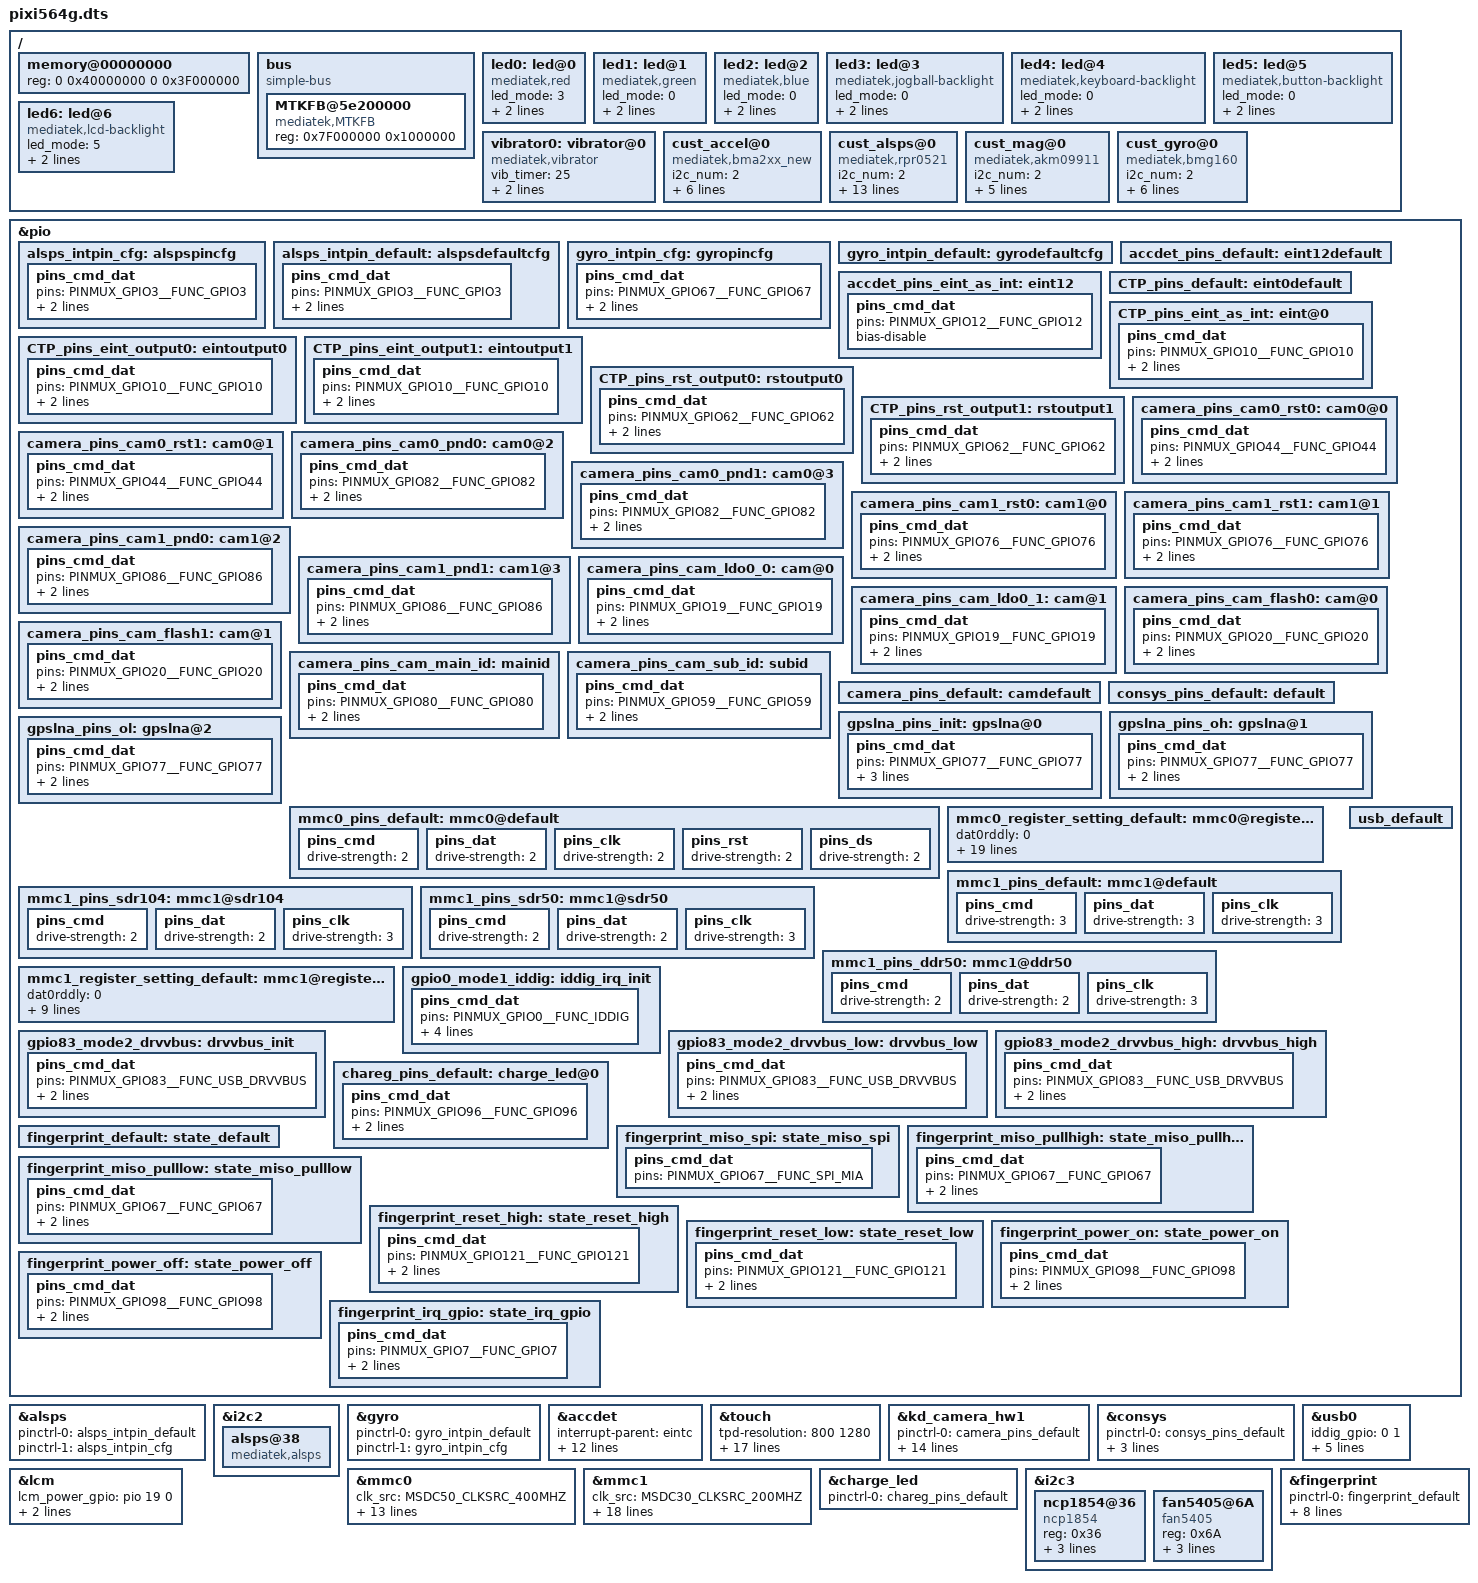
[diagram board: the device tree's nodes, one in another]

/dts-v1/;

#include "mt6735m.dtsi"
#include "pixi564g_bat_setting.dtsi"

/ {
memory@00000000 {
		device_type = "memory";
		reg = <0 0x40000000 0 0x3F000000>;
	};

	bus {
		compatible = "simple-bus";
		#address-cells = <1>;
		#size-cells = <1>;
		ranges = <0 0 0 0xffffffff>;

		MTKFB@5e200000 {
			compatible = "mediatek,MTKFB";
			reg = <0x7F000000 0x1000000>;
		};

	};
	led0:led@0 {
		compatible = "mediatek,red";
		led_mode = <3>;
		data = <1>;
		pwm_config = <0 0 0 0 0>;
	};
	led1:led@1 {
		compatible = "mediatek,green";
		led_mode = <0>;
		data = <1>;
		pwm_config = <0 0 0 0 0>;
	};
	led2:led@2 {
		compatible = "mediatek,blue";
		led_mode = <0>;
		data = <1>;
		pwm_config = <0 0 0 0 0>;
	};
	led3:led@3 {
		compatible = "mediatek,jogball-backlight";
		led_mode = <0>;
		data = <1>;
		pwm_config = <0 0 0 0 0>;
	};
	led4:led@4 {
		compatible = "mediatek,keyboard-backlight";
		led_mode = <0>;
		data = <1>;
		pwm_config = <0 0 0 0 0>;
	};
	led5:led@5 {
		compatible = "mediatek,button-backlight";
		led_mode = <0>;
		data = <1>;
		pwm_config = <0 0 0 0 0>;
	};
	led6:led@6 {
		compatible = "mediatek,lcd-backlight";
		led_mode = <5>;
		data = <1>;
		pwm_config = <0 0 0 0 0>;
	};
	vibrator0:vibrator@0 {
		compatible = "mediatek,vibrator";
		vib_timer = <25>;
		vib_limit = <9>;
		vib_vol= <5>;
	};
 /* sensor standardization */
	cust_accel@0 {
		compatible = "mediatek,bma2xx_new";
		i2c_num = <2>;
		i2c_addr = <0x18 0 0 0>;
		direction = <7>;
		power_id = <0xffff>;
		power_vol = <0>;
		firlen = <16>;
		is_batch_supported = <0>;
	};
/*
	cust_alsps@0 {
		compatible = "mediatek,apds9930";
		i2c_num = <2>;
		i2c_addr = <0x39 0x00 0x00 0x00>;
		polling_mode_ps = <0>;
		polling_mode_als = <1>;
		power_id = <0xffff>;
		power_vol = <0>;
		als_level = <1 2 5 10 20 30 40 80 200 300 400 600 1000 1600 2000>;
		als_value = <80 400 800 1200 1800 2000 2300 2300 12000 12000 12000 48000 48000 72000 81920 81920>;
		ps_threshold_high =  <90>;
		ps_threshold_low =  <70>;
		is_batch_supported_ps   = <0>;
		is_batch_supported_als  = <0>;
	};
*/
	cust_alsps@0 {
		compatible = "mediatek,rpr0521";
		i2c_num	= <2>;
		i2c_addr = <0x38 0 0 0>;
		polling_mode_ps	= <0>;
		polling_mode_als = <1>;
		power_id = <0xffff>;
		power_vol = <0>;
		als_level = <0 257 637 1027 2297 5588 6730 11301 20449 25768 31122 45552 57937 57937 57937>;
		als_value = <0 132 304 502 1004 2003 3006 5006 8004 10000 12000 16000 20000 20000 20000 20000>;
		ps_threshold_high = <1000>;
		ps_threshold_low = <999>;
		is_batch_supported_ps = <1>;
		is_batch_supported_als = <1>;
	};
	cust_mag@0 {
		compatible				= "mediatek,akm09911";
		i2c_num				= <2>;
		i2c_addr				= <0x0D 0 0 0>;
		direction				= <5>;
		power_id				= <0xffff>;
		power_vol				= <0>;
		is_batch_supported	= <0>;
		};
    cust_gyro@0 {
		compatible				= "mediatek,bmg160";
		i2c_num				= <2>;
		i2c_addr				= <0x66 0 0 0>;
		direction				= <4>;
		power_id				= <0xffff>;
		power_vol				= <0>;
		firlen					= <0>;
		is_batch_supported	= <0>;
		};
/*	cust_gyro@0 {
		compatible				= "mediatek,itg1010";
		i2c_num				= <2>;
		i2c_addr				= <0x68 0 0 0>;
		direction				= <3>;
		power_id				= <0xffff>;
		power_vol				= <0>;
		firlen					= <0>;
		is_batch_supported	= <0>;
		};
*/
};
/* sensor gpio standization */
&pio {
	alsps_intpin_cfg: alspspincfg {
		pins_cmd_dat {
			pins = <PINMUX_GPIO3__FUNC_GPIO3>;
			slew-rate = <0>;
			bias-pull-up = <00>;
		};
	};

	alsps_intpin_default: alspsdefaultcfg {
		pins_cmd_dat {
			pins = <PINMUX_GPIO3__FUNC_GPIO3>;
			slew-rate = <0>;
			bias-pull-up = <00>;
		};
	};

	gyro_intpin_cfg: gyropincfg {
		pins_cmd_dat {
			pins = <PINMUX_GPIO67__FUNC_GPIO67>;
			slew-rate = <0>;
			bias-pull-down = <00>;
		};
	};

	gyro_intpin_default: gyrodefaultcfg {

	};
};
&alsps {
	pinctrl-names = "default", "pin_cfg";
	pinctrl-0 = <&alsps_intpin_default>;
	pinctrl-1 = <&alsps_intpin_cfg>;
	status = "okay";
};
&i2c2 {
	alsps@38 {
		compatible = "mediatek,alsps";
		status = "okay";
	};
};

&gyro {
	pinctrl-names = "pin_default", "pin_cfg";
	pinctrl-0 = <&gyro_intpin_default>;
	pinctrl-1 = <&gyro_intpin_cfg>;
	status = "okay";

};
/* sensor end */

&accdet {
	interrupt-parent = <&eintc>;
	interrupts = <12 IRQ_TYPE_LEVEL_LOW>;
	eint-debounce = <256>;
	accdet-gpio = <&pio 12 0>;
	accdet-mic-vol = <3>;		/* [PLATFORM]-Add by TCTSZ.lizhi.wu, 2016.09.20, change micbias from 2.5 to 2.0*/
	headset-mode-setting = <0x500 0x500 1 0x1f0 0x800 0x800 0x20>;		/* [PLATFORM]-Add by TCTSZ.lizhi.wu, 2016.11.01, make micbias always on*/
	accdet-plugout-debounce = <20>;
	/*1:ACC mode, 2:low cost without in bias, 6:low cost with in bias*/
	accdet-mic-mode = <6>;
	/*0--MD_MAX--UP_MAX--DW_MAX*/
	headset-three-key-threshold = <0 80 220 500>;
	/*0--MD_MAX--VOICE_MAX--UP_MAX--DW_MAX*/
	headset-four-key-threshold = <0 58 121 192 450>;
	pinctrl-names = "default", "state_eint_as_int";
	pinctrl-0 = <&accdet_pins_default>;
	pinctrl-1 = <&accdet_pins_eint_as_int>;
	status = "okay";
};

&touch {
	tpd-resolution = <800 1280>;
	use-tpd-button = <0>;
	tpd-key-num = <3>;
	tpd-key-local= <139 172 158 0>;
	tpd-key-dim-local = <90 883 100 40 230 883 100 40 370 883 100 40 0 0 0 0>;
	tpd-max-touch-num = <5>;
	tpd-filter-enable = <1>;
	tpd-filter-pixel-density = <93>;
	tpd-filter-custom-prameters = <0 0 0 0 0 0 0 0 0 0 0 0>;
	tpd-filter-custom-speed = <0 0 0>;
	pinctrl-names = "default", "state_eint_as_int", "state_eint_output0", "state_eint_output1",
		"state_rst_output0", "state_rst_output1";
	pinctrl-0 = <&CTP_pins_default>;
	pinctrl-1 = <&CTP_pins_eint_as_int>;
	pinctrl-2 = <&CTP_pins_eint_output0>;
	pinctrl-3 = <&CTP_pins_eint_output1>;
	pinctrl-4 = <&CTP_pins_rst_output0>;
	pinctrl-5 = <&CTP_pins_rst_output1>;
	status = "okay";
};
&pio {
	accdet_pins_default: eint12default {
	};

	accdet_pins_eint_as_int: eint12 {
		pins_cmd_dat {
			pins = <PINMUX_GPIO12__FUNC_GPIO12>;
			bias-disable;
		};
	};

	CTP_pins_default: eint0default {
	};
	CTP_pins_eint_as_int: eint@0 {
		pins_cmd_dat {
			pins = <PINMUX_GPIO10__FUNC_GPIO10>;
			slew-rate = <0>;
			bias-disable;
		};
	};
	CTP_pins_eint_output0: eintoutput0 {
		pins_cmd_dat {
			pins = <PINMUX_GPIO10__FUNC_GPIO10>;
			slew-rate = <1>;
			output-low;
		};
	};
	CTP_pins_eint_output1: eintoutput1 {
		pins_cmd_dat {
			pins = <PINMUX_GPIO10__FUNC_GPIO10>;
			slew-rate = <1>;
			output-high;
		};
	};
	CTP_pins_rst_output0: rstoutput0 {
		pins_cmd_dat {
			pins = <PINMUX_GPIO62__FUNC_GPIO62>;
			slew-rate = <1>;
			output-low;
		};
	};
	CTP_pins_rst_output1: rstoutput1 {
		pins_cmd_dat {
			pins = <PINMUX_GPIO62__FUNC_GPIO62>;
			slew-rate = <1>;
			output-high;
		};
	};
};
/* TOUCH end */
/* CAMERA GPIO standardization */
&pio {
	camera_pins_cam0_rst0: cam0@0 {
	    pins_cmd_dat {
			pins = <PINMUX_GPIO44__FUNC_GPIO44>;/*GPIO_CAMERA_CMRST_PIN*/
			slew-rate = <1>; /*direction 0:in, 1:out*/
			output-low;/*direction out used only. output_low or high*/
		};
	};
	camera_pins_cam0_rst1: cam0@1 {
	    pins_cmd_dat {
			pins = <PINMUX_GPIO44__FUNC_GPIO44>;/*GPIO_CAMERA_CMRST_PIN*/
			slew-rate = <1>;
			output-high;
		};
	};
	camera_pins_cam0_pnd0: cam0@2 {
	    pins_cmd_dat {
			pins = <PINMUX_GPIO82__FUNC_GPIO82>;/*GPIO_CAMERA_CMPDN_PIN*/
			slew-rate = <1>;
			output-low;
		};
	};
	camera_pins_cam0_pnd1: cam0@3 {
	    pins_cmd_dat {
			pins = <PINMUX_GPIO82__FUNC_GPIO82>;/*GPIO_CAMERA_CMPDN_PIN*/
			slew-rate = <1>;
			output-high;
		};
	};
	camera_pins_cam1_rst0: cam1@0 {
	    pins_cmd_dat {
			pins = <PINMUX_GPIO76__FUNC_GPIO76>;/*GPIO_CAMERA_CMRST1_PIN*/
			slew-rate = <1>; /*direction 0:in, 1:out*/
			output-low;/*direction out used only. output_low or high*/
		};
	};
	camera_pins_cam1_rst1: cam1@1 {
	    pins_cmd_dat {
			pins = <PINMUX_GPIO76__FUNC_GPIO76>;/*GPIO_CAMERA_CMRST1_PIN*/
			slew-rate = <1>;
			output-high;
		};
	};
	camera_pins_cam1_pnd0: cam1@2 {
	    pins_cmd_dat {
			pins = <PINMUX_GPIO86__FUNC_GPIO86>;/*GPIO_CAMERA_CMPDN1_PIN*/
			slew-rate = <1>;
			output-low;
		};
	};
	camera_pins_cam1_pnd1: cam1@3 {
	    pins_cmd_dat {
			pins = <PINMUX_GPIO86__FUNC_GPIO86>;/*GPIO_CAMERA_CMPDN1_PIN*/
			slew-rate = <1>;
			output-high;
		};
	};
	camera_pins_cam_ldo0_0: cam@0 {
	    pins_cmd_dat {
			pins = <PINMUX_GPIO19__FUNC_GPIO19>;/*GPIO_SPI_MOSI_PIN*/
			slew-rate = <1>;
			output-low;
		};
	};
	camera_pins_cam_ldo0_1: cam@1 {
		pins_cmd_dat {
			pins = <PINMUX_GPIO19__FUNC_GPIO19>;/*GPIO_SPI_MOSI_PIN*/
			slew-rate = <1>;
			output-high;
		};
	};

	camera_pins_cam_flash0: cam@0 {
		pins_cmd_dat {
			pins = <PINMUX_GPIO20__FUNC_GPIO20>;
			slew-rate = <1>;
			output-low;
		};
	};

	camera_pins_cam_flash1: cam@1 {
		pins_cmd_dat {
			pins = <PINMUX_GPIO20__FUNC_GPIO20>;
			slew-rate = <1>;
			output-high;
		};
	};


	camera_pins_cam_main_id: mainid {
		pins_cmd_dat {
			pins = <PINMUX_GPIO80__FUNC_GPIO80>;
			slew-rate = <0>;
			bias-disable;
                        /*bias-pull-down = <00>;
                        output-low;
                        input-schmitt-enable = <0>;*/
		};
	};

	camera_pins_cam_sub_id: subid {
		pins_cmd_dat {
			pins = <PINMUX_GPIO59__FUNC_GPIO59>;
			slew-rate = <0>;
			bias-disable;
                       	/*bias-pull-down = <00>;
                        output-low;
                        input-schmitt-enable = <0>;*/
		};
	};

	camera_pins_default: camdefault {
	};

};

&kd_camera_hw1 {
	pinctrl-names = "default", "cam0_rst0", "cam0_rst1", "cam0_pnd0", "cam0_pnd1",
			"cam1_rst0", "cam1_rst1", "cam1_pnd0", "cam1_pnd1","cam_ldo0_0", "cam_ldo0_1","cam_flash0","cam_flash1","main_ctype","sub_ctype";
	pinctrl-0 = <&camera_pins_default>;
	pinctrl-1 = <&camera_pins_cam0_rst0>;
	pinctrl-2 = <&camera_pins_cam0_rst1>;
	pinctrl-3 = <&camera_pins_cam0_pnd0>;
	pinctrl-4 = <&camera_pins_cam0_pnd1>;
	pinctrl-5 = <&camera_pins_cam1_rst0>;
	pinctrl-6 = <&camera_pins_cam1_rst1>;
	pinctrl-7 = <&camera_pins_cam1_pnd0>;
	pinctrl-8 = <&camera_pins_cam1_pnd1>;
	pinctrl-9 = <&camera_pins_cam_ldo0_0>;
	pinctrl-10 = <&camera_pins_cam_ldo0_1>;
	pinctrl-11 = <&camera_pins_cam_flash0>;
	pinctrl-12 = <&camera_pins_cam_flash1>;
	pinctrl-13 = <&camera_pins_cam_main_id>;
	pinctrl-14 = <&camera_pins_cam_sub_id>;
	status = "okay";

};
/* CAMERA GPIO end */

/* CONSYS GPIO standardization */
&pio {
	consys_pins_default: default {

	};

	gpslna_pins_init: gpslna@0 {

	    pins_cmd_dat {
			pins = <PINMUX_GPIO77__FUNC_GPIO77>;
			slew-rate = <0>;
			bias-disable;
			output-low;
		};
	};

	gpslna_pins_oh: gpslna@1 {

	    pins_cmd_dat {
			pins = <PINMUX_GPIO77__FUNC_GPIO77>;
			slew-rate = <1>;
			output-high;
		};
	};

	gpslna_pins_ol: gpslna@2 {

	    pins_cmd_dat {
			pins = <PINMUX_GPIO77__FUNC_GPIO77>;
			slew-rate = <1>;
			output-low;
		};
	};

};

&consys {
	pinctrl-names = "default", "gps_lna_state_init", "gps_lna_state_oh", "gps_lna_state_ol";
	pinctrl-0 = <&consys_pins_default>;
	pinctrl-1 = <&gpslna_pins_init>;
	pinctrl-2 = <&gpslna_pins_oh>;
	pinctrl-3 = <&gpslna_pins_ol>;
	status = "okay";

};
/* CONSYS end */

/* mmc start */
&mmc0 {
		clk_src = /bits/ 8 <MSDC50_CLKSRC_400MHZ>;
		bus-width = <8>;
		max-frequency = <200000000>;
		cap-mmc-highspeed;
		msdc-sys-suspend;
		mmc-ddr-1_8v;
		mmc-hs200-1_8v;
		mmc-hs400-1_8v;
		non-removable;
		pinctl = <&mmc0_pins_default>;
		register_setting = <&mmc0_register_setting_default>;
		host_function = /bits/ 8 <MSDC_EMMC>;
		bootable;
		status = "okay";
};

&mmc1 {
		clk_src = /bits/ 8 <MSDC30_CLKSRC_200MHZ>;
		bus-width = <4>;
		max-frequency = <200000000>;
		msdc-sys-suspend;
		sd_need_power;
		cap-sd-highspeed;
		sd-uhs-sdr12;
		sd-uhs-sdr25;
		sd-uhs-sdr50;
		/*sd-uhs-sdr104;*/
		sd-uhs-ddr50;
		pinctl = <&mmc1_pins_default>;
		pinctl_sdr104 = <&mmc1_pins_sdr104>;
		pinctl_sdr50 = <&mmc1_pins_sdr50>;
		pinctl_ddr50 = <&mmc1_pins_ddr50>;
		register_setting = <&mmc1_register_setting_default>;
		host_function = /bits/ 8 <MSDC_SD>;
		cd_level = /bits/ 8 <MSDC_CD_LOW>;
		cd-gpios = <&pio 11 0>;
		status = "okay";
};

&pio {
	mmc0_pins_default: mmc0@default {
			pins_cmd {
				drive-strength = /bits/ 8 <2>;
			};
			pins_dat {
				drive-strength = /bits/ 8 <2>;
			};
			pins_clk {
				drive-strength = /bits/ 8 <2>;
			};
			pins_rst {
				drive-strength = /bits/ 8 <2>;
			};
			pins_ds {
				drive-strength = /bits/ 8 <2>;
			};
	};

	mmc0_register_setting_default: mmc0@register_default {
		dat0rddly      = /bits/ 8 <0>;
		dat1rddly      = /bits/ 8 <0>;
		dat2rddly      = /bits/ 8 <0>;
		dat3rddly      = /bits/ 8 <0>;
		dat4rddly      = /bits/ 8 <0>;
		dat5rddly      = /bits/ 8 <0>;
		dat6rddly      = /bits/ 8 <0>;
		dat7rddly      = /bits/ 8 <0>;
		datwrddly      = /bits/ 8 <0>;
		cmdrrddly      = /bits/ 8 <0>;
		cmdrddly       = /bits/ 8 <0>;
		cmd_edge = /bits/ 8 <MSDC_SMPL_FALLING>;
		rdata_edge = /bits/ 8 <MSDC_SMPL_FALLING>;
		wdata_edge = /bits/ 8 <MSDC_SMPL_FALLING>;

		ett-hs200-cells = <12>;
		ett-hs200-default = <OFFSET_MSDC_PATCH_BIT0	MSDC_PB0_INT_DAT_LATCH_CK_SEL 0x0
			OFFSET_MSDC_PATCH_BIT0	MSDC_PB0_CKGEN_MSDC_DLY_SEL   0x0
			OFFSET_MSDC_PATCH_BIT1	MSDC_PB1_CMD_RSP_TA_CNTR      0x1
			OFFSET_MSDC_IOCON		MSDC_IOCON_RSPL               0x0
			OFFSET_MSDC_PAD_TUNE0	MSDC_PAD_TUNE0_CMDRDLY        0x7
			OFFSET_MSDC_PAD_TUNE0	MSDC_PAD_TUNE0_CMDRRDLY       0xb
			OFFSET_MSDC_PATCH_BIT1		MSDC_PB1_WRDAT_CRCS_TA_CNTR   0x1
			OFFSET_MSDC_PAD_TUNE0	MSDC_PAD_TUNE0_DATWRDLY       0xb
			OFFSET_MSDC_IOCON			MSDC_IOCON_W_D0SPL            0x0
			OFFSET_MSDC_DAT_RDDLY0		MSDC_DAT_RDDLY0_D0            0x7
			OFFSET_MSDC_PAD_TUNE0	MSDC_PAD_TUNE0_DATRRDLY       0x9
			OFFSET_MSDC_IOCON		MSDC_IOCON_R_D_SMPL           0x0>;

		ett-hs400-cells = <8>;
		ett-hs400-default = <OFFSET_MSDC_PATCH_BIT0	MSDC_PB0_INT_DAT_LATCH_CK_SEL	0x0
			OFFSET_MSDC_PATCH_BIT0		MSDC_PB0_CKGEN_MSDC_DLY_SEL		0x0
			OFFSET_EMMC50_PAD_DS_TUNE	MSDC_EMMC50_PAD_DS_TUNE_DLY1	0x2
			OFFSET_EMMC50_PAD_DS_TUNE	MSDC_EMMC50_PAD_DS_TUNE_DLY3	0x10
			OFFSET_MSDC_PATCH_BIT1			MSDC_PB1_CMD_RSP_TA_CNTR	0x1
			OFFSET_MSDC_IOCON		MSDC_IOCON_RSPL				0x0
			OFFSET_MSDC_PAD_TUNE0			MSDC_PAD_TUNE0_CMDRDLY		0x6
			OFFSET_MSDC_PAD_TUNE0		MSDC_PAD_TUNE0_CMDRRDLY		0x6>;
	};

	mmc1_pins_default: mmc1@default {
			pins_cmd {
				drive-strength = /bits/ 8 <3>;
			};
			pins_dat {
				drive-strength = /bits/ 8 <3>;
			};
			pins_clk {
				drive-strength = /bits/ 8 <3>;
			};
	};

	mmc1_pins_sdr104: mmc1@sdr104 {
			pins_cmd {
				drive-strength = /bits/ 8 <2>;
			};
			pins_dat {
				drive-strength = /bits/ 8 <2>;
			};
			pins_clk {
				drive-strength = /bits/ 8 <3>;
			};
	};

	mmc1_pins_sdr50: mmc1@sdr50 {
			pins_cmd {
				drive-strength = /bits/ 8 <2>;
			};
			pins_dat {
				drive-strength = /bits/ 8 <2>;
			};
			pins_clk {
				drive-strength = /bits/ 8 <3>;
			};
	};

	mmc1_pins_ddr50: mmc1@ddr50 {
			pins_cmd {
				drive-strength = /bits/ 8 <2>;
			};
			pins_dat {
				drive-strength = /bits/ 8 <2>;
			};
			pins_clk {
				drive-strength = /bits/ 8 <3>;
			};
	};

	mmc1_register_setting_default: mmc1@register_default {
				dat0rddly      = /bits/ 8 <0>;
				dat1rddly      = /bits/ 8 <0>;
				dat2rddly      = /bits/ 8 <0>;
				dat3rddly      = /bits/ 8 <0>;
				datwrddly      = /bits/ 8 <0>;
				cmdrrddly      = /bits/ 8 <0>;
				cmdrddly       = /bits/ 8 <0>;
				cmd_edge = /bits/ 8 <MSDC_SMPL_FALLING>;
				rdata_edge = /bits/ 8 <MSDC_SMPL_FALLING>;
				wdata_edge = /bits/ 8 <MSDC_SMPL_FALLING>;
	};
};
/* mmc end */
/* USB GPIO Kernal Standardization start */
&pio {
	usb_default: usb_default {
	};
/* fan5405 charger bring up PR2817629*/
	gpio0_mode1_iddig: iddig_irq_init {
		pins_cmd_dat {
			pins = <PINMUX_GPIO0__FUNC_IDDIG>;
                        slew-rate = <0>;

                        bias-pull-down = <11>;
                        output-low;
                        input-schmitt-enable = <0>;
		};
	};

	gpio83_mode2_drvvbus: drvvbus_init {
		pins_cmd_dat {
			pins = <PINMUX_GPIO83__FUNC_USB_DRVVBUS>;
			slew-rate = <1>;
			bias-pull-up = <00>;
		};
	};

	gpio83_mode2_drvvbus_low: drvvbus_low {
		pins_cmd_dat {
			pins = <PINMUX_GPIO83__FUNC_USB_DRVVBUS>;
			slew-rate = <1>;
			output-low;
		};
	};

	gpio83_mode2_drvvbus_high: drvvbus_high {
		pins_cmd_dat {
			pins = <PINMUX_GPIO83__FUNC_USB_DRVVBUS>;
			slew-rate = <1>;
			output-high;
		};
	};
};

/*[1191997] support leds device init by device tree modify by liming.zhu at 20151223 bigen */
&charge_led {
        pinctrl-names = "chareg_pins_default";
        pinctrl-0 = <&chareg_pins_default>;
        status = "okay";
};

&pio {
        chareg_pins_default: charge_led@0 {
        pins_cmd_dat {
                pins = <PINMUX_GPIO96__FUNC_GPIO96>;
                slew-rate = <1>;
                output-high;
                };
        };
};
/*[1191997] support leds device init by device tree modify by liming.zhu at 20151223 end */

&usb0 {
	iddig_gpio = <0 1>;
	pinctrl-names = "usb_default", "iddig_irq_init", "drvvbus_init", "drvvbus_low", "drvvbus_high";
	pinctrl-0 = <&usb_default>;
	pinctrl-1 = <&gpio0_mode1_iddig>;
	pinctrl-2 = <&gpio83_mode2_drvvbus>;
	pinctrl-3 = <&gpio83_mode2_drvvbus_low>;
	pinctrl-4 = <&gpio83_mode2_drvvbus_high>;
	status = "okay";
};
/* USB GPIO Kernal Standardization end */
/* LCM set */
&lcm {
	lcm_power_gpio = <&pio 19 0>;
	lcm_reset_gpio = <&pio 146 0>;
	reg-lcm-supply = <&mt_pmic_vcama_ldo_reg>;
};
/* LCM end */

/* i2c start */
&i2c3 {
	ncp1854@36 {
		status = "okay";
		compatible = "ncp1854";
		reg = <0x36>;
		disable_ncp1854_fctry_mod = <1>;
		pinctrl-names = "drvvbus_init", "drvvbus_low";
		pinctrl-0 = <&gpio83_mode2_drvvbus>;
		pinctrl-1 = <&gpio83_mode2_drvvbus_low>;
	};
/* fan5405 charger bring up PR2817629*/
	fan5405@6A {
		status = "okay";
		compatible = "fan5405";
		reg = <0x6A>;
		disable_fan5405_fctry_mod = <1>;
		pinctrl-names = "drvvbus_init", "drvvbus_low";
		pinctrl-0 = <&gpio83_mode2_drvvbus>;
		pinctrl-1 = <&gpio83_mode2_drvvbus_low>;
	};
};
/* i2c end */

/* fingernprint added by ke.huang.sz 20160914 begin */
&fingerprint {
	pinctrl-names = "default", "miso_spi", "miso_pullhigh", "miso_pulllow", "reset_high", "reset_low", "power_on","power_off", "irq_gpio";
	pinctrl-0 = <&fingerprint_default>;
	pinctrl-1 = <&fingerprint_miso_spi>;
	pinctrl-2 = <&fingerprint_miso_pullhigh>;
	pinctrl-3 = <&fingerprint_miso_pulllow>;
	pinctrl-4 = <&fingerprint_reset_high>;
	pinctrl-5 = <&fingerprint_reset_low>;
	pinctrl-6 = <&fingerprint_power_on>;
	pinctrl-7 = <&fingerprint_power_off>;
	pinctrl-8 = <&fingerprint_irq_gpio>;
	status = "okay";
};

&pio {
	fingerprint_default: state_default {

	};

	fingerprint_miso_spi: state_miso_spi {
		pins_cmd_dat {
			pins = <PINMUX_GPIO67__FUNC_SPI_MIA>;
		};
	};

	fingerprint_miso_pullhigh: state_miso_pullhigh {
		pins_cmd_dat {
			pins = <PINMUX_GPIO67__FUNC_GPIO67>;
			slew-rate = <1>;
			output-high;
		};
	};

	fingerprint_miso_pulllow: state_miso_pulllow {
		pins_cmd_dat {
			pins = <PINMUX_GPIO67__FUNC_GPIO67>;
			slew-rate = <1>;
			output-low;
		};
	};

	fingerprint_reset_high: state_reset_high {
		pins_cmd_dat {
			pins = <PINMUX_GPIO121__FUNC_GPIO121>;
			slew-rate = <1>;
			output-high;
		};
	};

	fingerprint_reset_low: state_reset_low {
		pins_cmd_dat {
			pins = <PINMUX_GPIO121__FUNC_GPIO121>;
			slew-rate = <1>;
			output-low;
		};
	};

	fingerprint_power_on: state_power_on {
		pins_cmd_dat {
			pins = <PINMUX_GPIO98__FUNC_GPIO98>;
			slew-rate = <1>;
			output-high;
		};
	};

	fingerprint_power_off: state_power_off {
		pins_cmd_dat {
			pins = <PINMUX_GPIO98__FUNC_GPIO98>;
			slew-rate = <1>;
			output-low;
		};
	};
	fingerprint_irq_gpio: state_irq_gpio {
		pins_cmd_dat {
			pins = <PINMUX_GPIO7__FUNC_GPIO7>;
			slew-rate = <0>;
			bias-disable;
		};
	};
};
/* fignerprint added by ke.huang.sz 20160914 end*/
